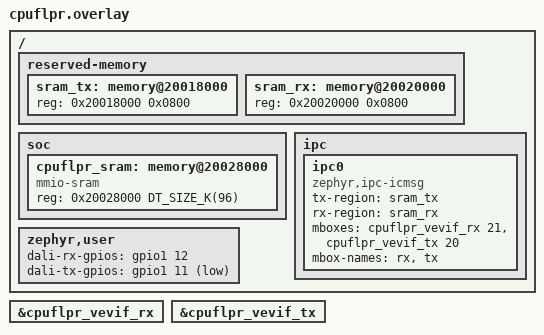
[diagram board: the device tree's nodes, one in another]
// SPDX-License-Identifier: Apache-2.0
/delete-node/ &cpuflpr_sram;

/ {
	reserved-memory {
		#address-cells = <1>;
		#size-cells = <1>;

		sram_tx: memory@20018000 {
			reg = <0x20018000 0x0800>;
		};

		sram_rx: memory@20020000 {
			reg = <0x20020000 0x0800>;
		};
	};

	soc {
		cpuflpr_sram: memory@20028000 {
			compatible = "mmio-sram";
			reg = <0x20028000 DT_SIZE_K(96)>;
			#address-cells = <1>;
			#size-cells = <1>;
			ranges = <0x0 0x20028000 0x18000>;
			status = "okay";
		};
	};

	ipc {
		ipc0: ipc0 {
			compatible = "zephyr,ipc-icmsg";
			tx-region = <&sram_tx>;
			rx-region = <&sram_rx>;
			mboxes = <&cpuflpr_vevif_rx 21>, <&cpuflpr_vevif_tx 20>;
			mbox-names = "rx", "tx";
			status = "okay";
		};
	};

	zephyr,user {
		dali-rx-gpios = <&gpio1 12 GPIO_ACTIVE_HIGH>;
		dali-tx-gpios = <&gpio1 11 GPIO_ACTIVE_LOW>;
	};
};

&cpuflpr_vevif_rx {
	status = "okay";
};

&cpuflpr_vevif_tx {
	status = "okay";
};
